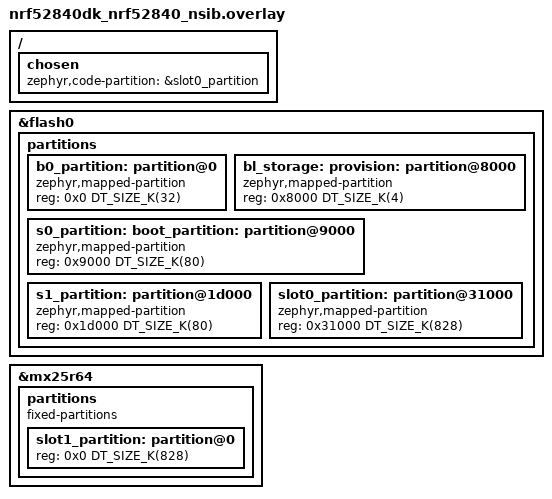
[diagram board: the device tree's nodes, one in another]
/*
 * Copyright (c) 2026 Nordic Semiconductor ASA
 *
 * SPDX-License-Identifier: LicenseRef-Nordic-5-Clause
 */

&flash0 {
	/delete-node/ partitions;

	partitions {
		ranges;
		#address-cells = <1>;
		#size-cells = <1>;

		b0_partition: partition@0 {
			compatible = "zephyr,mapped-partition";
			reg = <0x0 DT_SIZE_K(32)>;
		};

		bl_storage: provision: partition@8000 {
			compatible = "zephyr,mapped-partition";
			reg = <0x8000 DT_SIZE_K(4)>;
		};

		s0_partition: boot_partition: partition@9000 {
			compatible = "zephyr,mapped-partition";
			reg = <0x9000 DT_SIZE_K(80)>;
		};

		s1_partition: partition@1d000 {
			compatible = "zephyr,mapped-partition";
			reg = <0x1d000 DT_SIZE_K(80)>;
		};

		slot0_partition: partition@31000 {
			compatible = "zephyr,mapped-partition";
			reg = <0x31000 DT_SIZE_K(828)>;
		};
	};
};

&mx25r64 {
	status = "okay";

	partitions {
		compatible = "fixed-partitions";
		#address-cells = <1>;
		#size-cells = <1>;

		slot1_partition: partition@0 {
			reg = <0x0 DT_SIZE_K(828)>;
		};
	};
};

/ {
	chosen {
		zephyr,code-partition = &slot0_partition;
	};
};
